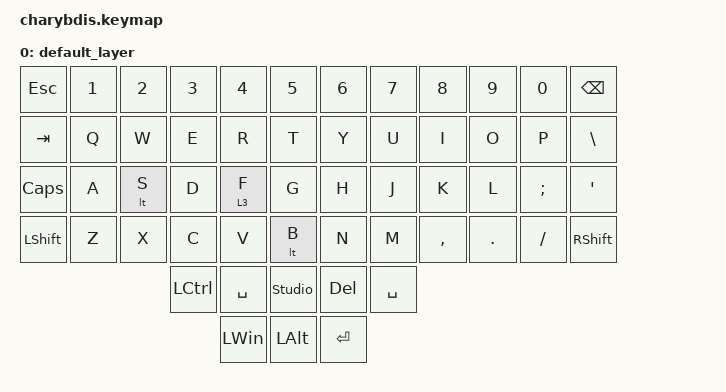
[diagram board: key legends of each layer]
#include <behaviors.dtsi>
#include <dt-bindings/zmk/keys.h>
#include <dt-bindings/zmk/rgb.h>

/ {

    keymap {
        compatible = "zmk,keymap";

        default_layer {
            bindings = <
                &kp ESC         &kp N1  &kp N2   &kp N3            &kp N4        &kp N5          &kp N6      &kp N7     &kp N8     &kp N9   &kp N0    &kp BACKSPACE
                &kp TAB         &kp Q   &kp W    &kp E             &kp R         &kp T           &kp Y       &kp U      &kp I      &kp O    &kp P     &kp BSLH
                &kp CAPSLOCK    &kp A   &lt S    &kp D             &lt 3 F       &kp G           &kp H       &kp J      &kp K      &kp L    &kp SEMI  &kp SQT
                &kp LEFT_SHIFT  &kp Z   &kp X    &kp C             &kp V         &lt B           &kp N       &kp M      &kp COMMA  &kp DOT  &kp FSLH  &kp RIGHT_SHIFT
                                                 &kp LEFT_CONTROL  &kp SPACE     &studio_unlock  &kp DELETE  &kp SPACE
                                                                   &kp LEFT_WIN  &kp LEFT_ALT    &kp ENTER
            >;
        };

};
